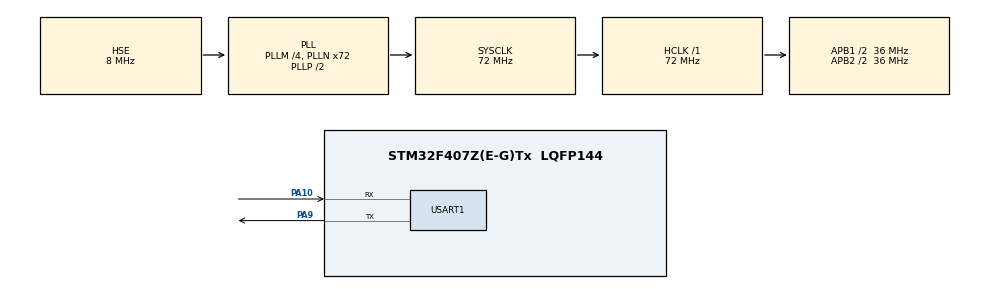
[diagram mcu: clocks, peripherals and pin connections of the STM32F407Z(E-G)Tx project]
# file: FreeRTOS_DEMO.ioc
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Dma.Request0=USART1_RX
Dma.USART1_RX.0.Direction=DMA_PERIPH_TO_MEMORY
Dma.USART1_RX.0.FIFOMode=DMA_FIFOMODE_DISABLE
Dma.USART1_RX.0.Instance=DMA2_Stream2
Dma.USART1_RX.0.MemDataAlignment=DMA_MDATAALIGN_BYTE
Dma.USART1_RX.0.MemInc=DMA_MINC_ENABLE
Dma.USART1_RX.0.Mode=DMA_CIRCULAR
Dma.USART1_RX.0.PeriphDataAlignment=DMA_PDATAALIGN_BYTE
Dma.USART1_RX.0.PeriphInc=DMA_PINC_DISABLE
Dma.USART1_RX.0.Priority=DMA_PRIORITY_LOW
Mcu.Family=STM32F4
Mcu.Name=STM32F407Z(E-G)Tx
Mcu.Package=LQFP144
NVIC.DMA2_Stream2_IRQn=true\:0\:0\:false\:false\:true\:false\:true\:true
NVIC.PriorityGroup=NVIC_PRIORITYGROUP_4
NVIC.TIM2_IRQn=true\:15\:0\:false\:false\:true\:false\:true\:true
NVIC.TIM7_IRQn=true\:3\:0\:true\:false\:true\:true\:true\:true
NVIC.TimeBase=TIM2_IRQn
NVIC.TimeBaseIP=TIM2
NVIC.USART1_IRQn=true\:2\:0\:true\:false\:true\:true\:true\:true
PA10.Mode=Asynchronous
PA10.Signal=USART1_RX
PA13.Mode=Serial_Wire
PA13.Signal=SYS_JTMS-SWDIO
PA14.Mode=Serial_Wire
PA14.Signal=SYS_JTCK-SWCLK
PA9.Mode=Asynchronous
PA9.Signal=USART1_TX
PH0-OSC_IN.Mode=HSE-External-Oscillator
PH0-OSC_IN.Signal=RCC_OSC_IN
PH1-OSC_OUT.Mode=HSE-External-Oscillator
PH1-OSC_OUT.Signal=RCC_OSC_OUT
ProjectManager.HeapSize=0x200
ProjectManager.StackSize=0x400
ProjectManager.TargetToolchain=MDK-ARM V5.32
RCC.48MHZClocksFreq_Value=36000000
RCC.AHBFreq_Value=72000000
RCC.APB1CLKDivider=RCC_HCLK_DIV2
RCC.APB1Freq_Value=36000000
RCC.APB1TimFreq_Value=72000000
RCC.APB2CLKDivider=RCC_HCLK_DIV2
RCC.APB2Freq_Value=36000000
RCC.APB2TimFreq_Value=72000000
RCC.CortexFreq_Value=72000000
RCC.HCLKFreq_Value=72000000
RCC.HSE_VALUE=8000000
RCC.HSI_VALUE=16000000
RCC.LSE_VALUE=32768
RCC.PLLM=4
RCC.PLLN=72
RCC.PLLSourceVirtual=RCC_PLLSOURCE_HSE
RCC.SYSCLKFreq_VALUE=72000000
RCC.SYSCLKSource=RCC_SYSCLKSOURCE_PLLCLK
RCC.VCOOutputFreq_Value=144000000
TIM7.AutoReloadPreload=TIM_AUTORELOAD_PRELOAD_DISABLE
TIM7.Period=10000
TIM7.Prescaler=7200-1
USART1.VirtualMode=VM_ASYNC
VP_SYS_VS_tim2.Mode=TIM2
VP_TIM7_VS_ClockSourceINT.Mode=Enable_Timer
board=custom

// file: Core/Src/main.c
/* USER CODE BEGIN Header */
/**
 ******************************************************************************
 * @file           : main.c
 * @brief          : Main program body
 ******************************************************************************
 * @attention
 *
 * Copyright (c) 2024 STMicroelectronics.
 * All rights reserved.
 *
 * This software is licensed under terms that can be found in the LICENSE file
 * in the root directory of this software component.
 * If no LICENSE file comes with this software, it is provided AS-IS.
 *
 ******************************************************************************
 */
/* USER CODE END Header */
#include "main.h"
#include "dma.h"
#include "tim.h"
#include "usart.h"
#include "gpio.h"

/* USER CODE BEGIN Includes */
#include "bsp_config.h"
/* USER CODE END Includes */

/* USER CODE BEGIN PV */
static TaskHandle_t AppTaskCreate_Handle = NULL; /* 创建任务句柄 */
static TaskHandle_t LED1_Task_Handle = NULL;      /* LED1_Task 任务句柄 */
static TaskHandle_t LED2_Task_Handle = NULL;      /* LED2_Task 任务句柄 */
static TaskHandle_t CPU_Task_Handle = NULL;        /* CPU_Task 任务句柄 */

/* USER CODE END PV */

void SystemClock_Config(void);
/* USER CODE BEGIN PFP */
static void AppTaskCreate(void);              /* 用于创建任务 */
static void LED1_Task(void *pvParameters);     /* LED1_Task 任务实现 */
static void LED2_Task(void *pvParameters);     /* LED2_Task 任务实现 */
static void CPU_Task(void *pvParameters);     /* CPU_Task 任务实现 */
/* USER CODE END PFP */

int main(void)
{
    /* USER CODE BEGIN 1 */
    BaseType_t xReturn = pdPASS;
    /* USER CODE END 1 */

    /* MCU Configuration--------------------------------------------------------*/

    /* Reset of all peripherals, Initializes the Flash interface and the Systick. */
    HAL_Init();

    /* Configure the system clock */
    SystemClock_Config();

    /* Initialize all configured peripherals */
    MX_GPIO_Init();
    MX_DMA_Init();
    MX_USART1_UART_Init();
    MX_TIM7_Init();
    /* USER CODE BEGIN 2 */
    BSP_LED_Init();
    BSP_KEY_Init();
    BSP_FREERTOS_TIMBASE_Init();
    HAL_TIM_Base_Start_IT(&htim7);

    printf("\n- Program Start -\n");

    xReturn = xTaskCreate((TaskFunction_t)AppTaskCreate,
                          "AppTaskCreate",
                          512,
                          NULL,
                          1,
                          &AppTaskCreate_Handle);
    if (pdPASS == xReturn)
    {
        printf("AppTaskCreate task create success!\n");
        vTaskStartScheduler();
    }
    else
        printf("AppTaskCreate task create failed!\n");
    /* USER CODE END 2 */

    /* Infinite loop */
    while (1)
    {

    }
}

void SystemClock_Config(void)
{
    RCC_OscInitTypeDef RCC_OscInitStruct = {0};
    RCC_ClkInitTypeDef RCC_ClkInitStruct = {0};

    /** Configure the main internal regulator output voltage
     */
    __HAL_RCC_PWR_CLK_ENABLE();
    __HAL_PWR_VOLTAGESCALING_CONFIG(PWR_REGULATOR_VOLTAGE_SCALE1);

    /** Initializes the RCC Oscillators according to the specified parameters
     * in the RCC_OscInitTypeDef structure.
     */
    RCC_OscInitStruct.OscillatorType = RCC_OSCILLATORTYPE_HSE;
    RCC_OscInitStruct.HSEState = RCC_HSE_ON;
    RCC_OscInitStruct.PLL.PLLState = RCC_PLL_ON;
    RCC_OscInitStruct.PLL.PLLSource = RCC_PLLSOURCE_HSE;
    RCC_OscInitStruct.PLL.PLLM = 4;
    RCC_OscInitStruct.PLL.PLLN = 72;
    RCC_OscInitStruct.PLL.PLLP = RCC_PLLP_DIV2;
    RCC_OscInitStruct.PLL.PLLQ = 4;
    if (HAL_RCC_OscConfig(&RCC_OscInitStruct) != HAL_OK)
    {
        Error_Handler();
    }

    /** Initializes the CPU, AHB and APB buses clocks
     */
    RCC_ClkInitStruct.ClockType = RCC_CLOCKTYPE_HCLK | RCC_CLOCKTYPE_SYSCLK | RCC_CLOCKTYPE_PCLK1 | RCC_CLOCKTYPE_PCLK2;
    RCC_ClkInitStruct.SYSCLKSource = RCC_SYSCLKSOURCE_PLLCLK;
    RCC_ClkInitStruct.AHBCLKDivider = RCC_SYSCLK_DIV1;
    RCC_ClkInitStruct.APB1CLKDivider = RCC_HCLK_DIV2;
    RCC_ClkInitStruct.APB2CLKDivider = RCC_HCLK_DIV2;

    if (HAL_RCC_ClockConfig(&RCC_ClkInitStruct, FLASH_LATENCY_2) != HAL_OK)
    {
        Error_Handler();
    }
}

/* USER CODE BEGIN 4 */
static void AppTaskCreate(void)
{
    BaseType_t xReturn = pdPASS;

    taskENTER_CRITICAL();

    xReturn = xTaskCreate((TaskFunction_t)LED1_Task,
                          "LED1_Task",
                          512,
                          NULL,
                          2,
                          &LED1_Task_Handle);
    if (pdPASS == xReturn)
        printf("LED1_Task task create success!\n");

    xReturn = xTaskCreate((TaskFunction_t)LED2_Task,
                          "LED2_Task",
                          512,
                          NULL,
                          3,
                          &LED2_Task_Handle);
    if (pdPASS == xReturn)
        printf("LED2_Task task create success!\n");

    xReturn = xTaskCreate((TaskFunction_t)CPU_Task,
                          "CPU_Task",
                          512,
                          NULL,
                          4,
                          &CPU_Task_Handle);
    if (pdPASS == xReturn)
        printf("CPU_Task task create success!\n");

    vTaskDelete(NULL);

    taskEXIT_CRITICAL();
}

static void LED1_Task(void *pvParameters)
{
    while (1)
    {
        __BSP_LED1_FICKER(100);
        printf("LED1_Task is running!\r\n");
    }
}

static void LED2_Task(void *pvParameters)
{
    while (1)
    {
        __BSP_LED2_FICKER(100);
        printf("LED2_Task is running!\r\n");
    }
}

static void CPU_Task(void *pvParameters)
{
    uint8_t CPU_RunInfo[400];
    while (1)
    {
        memset(CPU_RunInfo, 0, 400);

        // 获取任务运行时间信息
        vTaskList((char *)&CPU_RunInfo);

        printf("-----------------------------------------\r\n");
        printf("任务名  任务状态  优先级  剩余栈  任务序号\r\n");
        printf("%s", CPU_RunInfo);
        printf("-----------------------------------------\r\n");

        memset(CPU_RunInfo, 0, 400);

        vTaskGetRunTimeStats((char *)&CPU_RunInfo);

        printf("任务名  运行计数  使用率\r\n");
        printf("%s", CPU_RunInfo);
        printf("-----------------------------------------\r\n");

        vTaskDelay(1000);
    }
}
/* USER CODE END 4 */

void HAL_TIM_PeriodElapsedCallback(TIM_HandleTypeDef *htim)
{
    if (htim->Instance == TIM2)
    {
        HAL_IncTick();
    }
}

void Error_Handler(void)
{
    __disable_irq();
    while (1)
    {
    }
}
